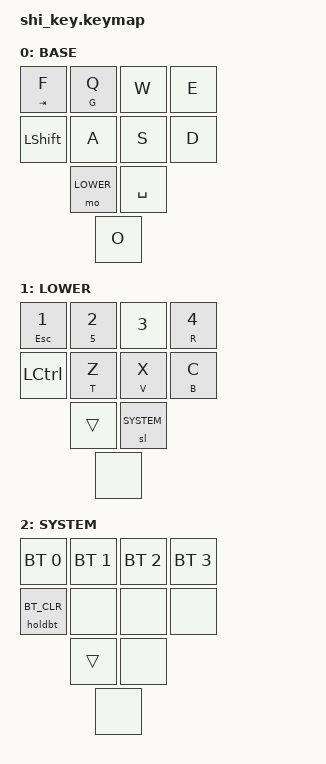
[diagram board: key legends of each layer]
#include <behaviors.dtsi>
#include <dt-bindings/zmk/keys.h>
#include <dt-bindings/zmk/bt.h>
#include <dt-bindings/zmk/outputs.h>

#define DEFAULT 0
#define LOWER   1
#define SYSTEM  2

&sl {
    release-after-ms = <1500>;
};

/ {
    behaviors {
        holdbt: hold_bt {
            compatible = "zmk,behavior-hold-tap";
            label = "HBT";
            #binding-cells = <2>;
            flavor = "tap-preferred";
            tapping-term-ms = <500>;
            quick-tap-ms = <200>;
            bindings = <&bt>, <&none>;
            hold-trigger-key-positions = <1>;
        };

        hm: homerow_mods {
            compatible = "zmk,behavior-hold-tap";
            label = "HOMEROW_MODS";
            #binding-cells = <2>;
            tapping-term-ms = <150>;
            quick-tap-ms = <0>;
            flavor = "tap-preferred";
            bindings = <&kp>, <&kp>;
        };
    };

    keymap {
      compatible = "zmk,keymap";

      default_layer {
        // -------------------------
        // | F/TAB   | Q/G |  W  |  E  |
        // | SHIFT   |  A  |  S  |  D  |
        //                  | LWR | SPC |
        bindings = <
          &mt TAB F &mt G Q &kp W &kp E
          &kp LSHIFT &kp A &kp S &kp D
                      &mo LOWER &kp SPACE
                                &kp O
                              >;
          label = "BASE";
      };

      lower_layer {
        // -------------------------
        // | 1/ESC |  2/5  |  3     |  4/R  |
        // | LCTRL |  Z/T |  X/V   |  C/B  |
        //                 | trans  | SYSTEM |

        bindings = <
          &mt ESC N1 &mt N5 N2 &kp N3 &mt R N4
          &kp LCTRL &mt T Z &mt V X &mt B C
                    &trans &sl SYSTEM
                              &none
                              >;
          label = "LOWER";
      };

      system_layer {
        // -------------------------
        // | BT1 | BT2 | BT3   | BT4 |
        // | BTC |  -  |  -    |  -  |
        //             | trans |  -  |

        bindings = <
          &bt BT_SEL 0 &bt BT_SEL 1 &bt BT_SEL 2 &bt BT_SEL 3
          &holdbt BT_CLR &none &none &none
                              &trans &none
                                      &none
                              >;
          label = "SYSTEM";
      };

      // number_layer {
      //   // -------------------------
      //   // |  1  |  2  |  3  |  4  |
      //   // |  5  |  6  |  7  |  8  |
      //   //             |  9  |  0  |

      //   bindings = <
      //     &bt BT_SEL 0 &bt BT_SEL 1 &bt BT_SEL 2 &bt BT_SEL 3
      //     &bt BT_CLR &none &kp Z &kp X
      //               &trans &none
      //                         >;
      //     label = "Number";
      // };

    };
};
